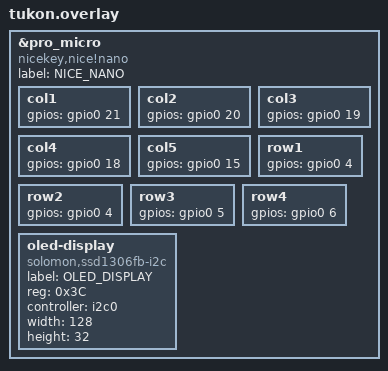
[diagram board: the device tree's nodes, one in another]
&pro_micro {
    compatible = "nicekey,nice!nano";
    label = "NICE_NANO";

    col1: col1 { gpios = <&gpio0 21 GPIO_ACTIVE_HIGH>; };
    col2: col2 { gpios = <&gpio0 20 GPIO_ACTIVE_HIGH>; };
    col3: col3 { gpios = <&gpio0 19 GPIO_ACTIVE_HIGH>; };
    col4: col4 { gpios = <&gpio0 18 GPIO_ACTIVE_HIGH>; };
    col5: col5 { gpios = <&gpio0 15 GPIO_ACTIVE_HIGH>; };

    row1: row1 { gpios = <&gpio0 4 GPIO_ACTIVE_HIGH>; };
    row2: row2 { gpios = <&gpio0 4 GPIO_ACTIVE_HIGH>; };
    row3: row3 { gpios = <&gpio0 5 GPIO_ACTIVE_HIGH>; };
    row4: row4 { gpios = <&gpio0 6 GPIO_ACTIVE_HIGH>; };

    /* OLED Display */
    oled-display {
        compatible = "solomon,ssd1306fb-i2c";
        label = "OLED_DISPLAY";
        reg = <0x3C>;
        controller = <&i2c0>;
        width = <128>;
        height = <32>;
    };
};


RC(3,3), RC, x, x
x, x,
x
x, x, x
x, x,
